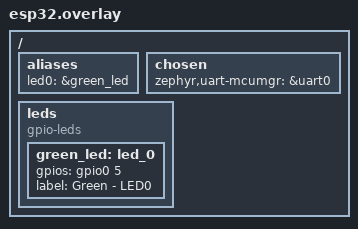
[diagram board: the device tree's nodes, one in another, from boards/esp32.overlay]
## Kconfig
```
config LED_BLINK_PERIOD
    int "Define Led Blink Period in ms"
    default 1000

source "Kconfig.zephyr"
```

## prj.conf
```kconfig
# Enable mcumgr.
CONFIG_MCUMGR=y

# Some command handlers require a large stack.
CONFIG_SYSTEM_WORKQUEUE_STACK_SIZE=2304
CONFIG_MAIN_STACK_SIZE=2048

# Ensure an MCUboot-compatible binary is generated.
CONFIG_BOOTLOADER_MCUBOOT=y

# Enable flash operations.
CONFIG_FLASH=y

# Enable most core commands.
CONFIG_MCUMGR_CMD_IMG_MGMT=y
CONFIG_MCUMGR_CMD_OS_MGMT=y

# Enable logging
CONFIG_LOG=y
CONFIG_MCUBOOT_UTIL_LOG_LEVEL_WRN=y

# Enable the serial mcumgr transport.
CONFIG_MCUMGR_SMP_UART=y

CONFIG_MCUBOOT_IMAGE_VERSION="0.0.1"
```

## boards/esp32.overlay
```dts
/ {
    aliases {
        led0 = &green_led;
    };
    chosen {
        zephyr,uart-mcumgr = &uart0;
    };
    leds {
        compatible = "gpio-leds";
        green_led: led_0 {
        gpios = <&gpio0 5 GPIO_ACTIVE_HIGH>;
        label = "Green - LED0";
        };
    };
};
```

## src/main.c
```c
/*
 * Copyright (c) 2022 Joao Dullius
 *
 * SPDX-License-Identifier: Apache-2.0
 */

#include <zephyr.h>
#include <drivers/gpio.h>

#include <stats/stats.h>

#include <os_mgmt/os_mgmt.h>
#include <img_mgmt/img_mgmt.h>
#include <mgmt/mcumgr/smp_bt.h>

#define LED0_NODE DT_ALIAS(led0)

const struct gpio_dt_spec led = GPIO_DT_SPEC_GET(LED0_NODE, gpios);

void main(void)
{
    int ret;

    printk("Hello Led!\n");

    os_mgmt_register_group();
    img_mgmt_register_group();

    if (!device_is_ready(led.port)) {
        return;
    }

    ret = gpio_pin_configure_dt(&led, GPIO_OUTPUT_ACTIVE);
	if (ret < 0) {
		return;
	}

    while (1) {
        ret = gpio_pin_toggle_dt(&led);
        if (ret < 0) {
            return;
        }
        k_msleep(CONFIG_LED_BLINK_PERIOD);
    }
}
```
